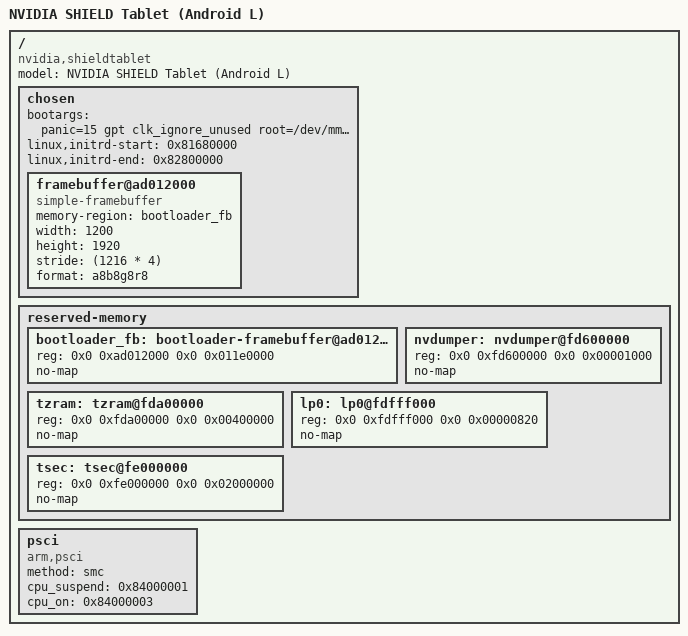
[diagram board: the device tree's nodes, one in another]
// SPDX-License-Identifier: GPL-2.0
/dts-v1/;

#include "tegra124-nvidia-shieldtablet.dtsi"

/ {
	model = "NVIDIA SHIELD Tablet (Android L)";
	// "nvidia,shieldtablet" goes first to keep the same Wi-Fi/Bluetooth firmware blob naming.
	compatible = "nvidia,shieldtablet", "nvidia,shieldtablet-l", "nvidia,tegra124";

	chosen {
		bootargs = "panic=15 gpt clk_ignore_unused root=/dev/mmcblk0p23 rw rootwait rootflags=defaults,noatime,nodiratime loop=media/0/Linux/linux.img loopflags=subvol=/pmos,compress=zstd:1,commit=120,discard=async,noatime,nodiratime";

		linux,initrd-start = <0x81680000>;
		linux,initrd-end = <0x82800000>;

		framebuffer@ad012000 {
			compatible = "simple-framebuffer";
			memory-region = <&bootloader_fb>;
			width = <1200>;
			height = <1920>;
			stride = <(1216 * 4)>;
			format = "a8b8g8r8";
		};
	};

	reserved-memory {
		#address-cells = <2>;
		#size-cells = <2>;
		ranges;

		bootloader_fb: bootloader-framebuffer@ad012000 {
			reg = <0x0 0xad012000 0x0 0x011e0000>;
			no-map;
		};

		nvdumper: nvdumper@fd600000 {
			reg = <0x0 0xfd600000 0x0 0x00001000>;
			no-map;
		};

		/* nck@fd700000 {
			reg = <0x0 0xfd700000 0x0 0x00100000>;
			no-map;
		}; */

		tzram: tzram@fda00000 {
			reg = <0x0 0xfda00000 0x0 0x00400000>;
			no-map;
		};

		lp0: lp0@fdfff000 {
			reg = <0x0 0xfdfff000 0x0 0x00000820>;
			no-map;
		};

		tsec: tsec@fe000000 {
			reg = <0x0 0xfe000000 0x0 0x02000000>;
			no-map;
		};
	};

	/*
	 * A `psci` node is present in this file even though PSCI is NOT used to
	 * power on CPU1-3 - on this board's (Android L) bootloader, PSCI CPU_ON
	 * claims success but never actually powers them on. Do not remove the
	 * psci node thinking it's unused: the kernel still needs it for one
	 * thing - registering its reset vector with firmware, via a CPU_ON call
	 * targeting CPU0 (already running) rather than the CPUs actually being
	 * booted. Actual CPU1-3 bring-up happens directly via PMC instead.
	 */
	psci {
		compatible = "arm,psci";
		method = "smc";
		cpu_suspend = <0x84000001>;
		cpu_on = <0x84000003>;
	};
};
